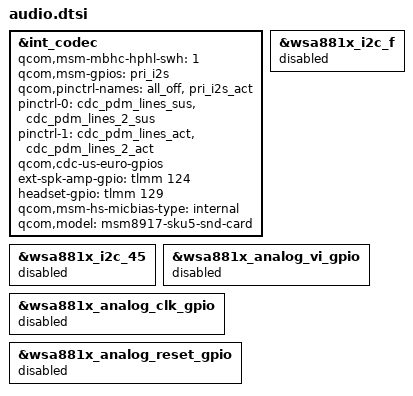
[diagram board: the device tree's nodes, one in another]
&int_codec {
	status = "okay";
	qcom,msm-mbhc-hphl-swh = <1>;
	qcom,msm-gpios =
		"pri_i2s";
	qcom,pinctrl-names =
		"all_off",
		"pri_i2s_act";
	pinctrl-names =
		"all_off",
		"pri_i2s_act";
	pinctrl-0 = <&cdc_pdm_lines_sus &cdc_pdm_lines_2_sus>;
	pinctrl-1 = <&cdc_pdm_lines_act &cdc_pdm_lines_2_act>;
	qcom,cdc-us-euro-gpios;
	ext-spk-amp-gpio = <&tlmm 124 0>;
	headset-gpio = <&tlmm 129 0>;
	qcom,msm-hs-micbias-type = "internal";

	/delete-property/ asoc-wsa-codec-names;
	/delete-property/ asoc-wsa-codec-prefixes;
	/delete-property/ msm-vdd-wsa-switch-supply;
	/delete-property/ qcom,msm-vdd-wsa-switch-voltage;
	/delete-property/ qcom,msm-vdd-wsa-switch-current;
};

&wsa881x_i2c_f {
        status = "disabled";
};

&wsa881x_i2c_45 {
        status = "disabled";
};

&wsa881x_analog_vi_gpio {
        status = "disabled";
};

&wsa881x_analog_clk_gpio {
        status = "disabled";
};

&wsa881x_analog_reset_gpio {
        status = "disabled";
};

&int_codec {
	qcom,model = "msm8917-sku5-snd-card";
};
